# ATmega16U4 device description
Architecture: AVR8; Family: megaAVR
Registers are 8-bit, access not given, no defined reset value unless marked. A register's access mark holds for its fields unless they carry their own. Offsets are from the block's base; [hi:lo] are bit positions.

## BOOT_LOAD — Bootloader
Instances: BOOT_LOAD 0x00
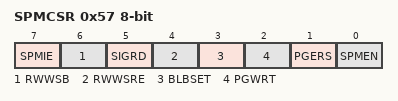
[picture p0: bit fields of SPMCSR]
0x57 SPMCSR — Store Program Memory Control Register
  [7] SPMIE — SPM Interrupt Enable
  [6] RWWSB — Read While Write Section Busy
  [5] SIGRD — Signature Row Read
  [4] RWWSRE — Read While Write section read enable
  [3] BLBSET — Boot Lock Bit Set
  [2] PGWRT — Page Write
  [1] PGERS — Page Erase
  [0] SPMEN — Store Program Memory Enable

## EEPROM
Instances: EEPROM 0x00
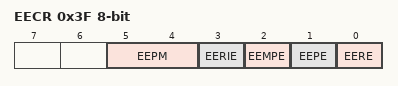
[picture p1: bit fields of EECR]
0x3F EECR — EEPROM Control Register
  [5:4] EEPM — EEPROM Programming Mode Bits
    0=Erase and Write in one operation; 1=Erase Only; 2=Write Only
  [3] EERIE — EEPROM Ready Interrupt Enable
  [2] EEMPE — EEPROM Master Write Enable
  [1] EEPE — EEPROM Write Enable
  [0] EERE — EEPROM Read Enable
0x40 EEDR — EEPROM Data Register
  [7:0] EEDR — EEPROM Data Bits
0x41 EEAR 16-bit — EEPROM Address Register Low Bytes
  [11:0] EEAR — EEPROM Address Bits

## TC0 (TC8 module) — Timer/Counter, 8-bit
Instances: TC0 0x00
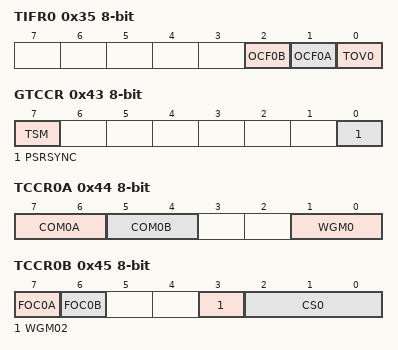
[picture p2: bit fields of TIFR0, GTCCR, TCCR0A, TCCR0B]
0x35 TIFR0 — Timer/Counter0 Interrupt Flag register
  [2] OCF0B — Timer/Counter0 Output Compare Flag 0B
  [1] OCF0A — Timer/Counter0 Output Compare Flag 0A
  [0] TOV0 — Timer/Counter0 Overflow Flag
0x43 GTCCR — General Timer/Counter Control Register
  [7] TSM — Timer/Counter Synchronization Mode
  [0] PSRSYNC — Prescaler Reset Timer/Counter1 and Timer/Counter0
0x44 TCCR0A — Timer/Counter Control Register A
  [7:6] COM0A — Compare Output Mode, Phase Correct PWM Mode
  [5:4] COM0B — Compare Output Mode, Fast PWm
  [1:0] WGM0 — Waveform Generation Mode
0x45 TCCR0B — Timer/Counter Control Register B
  [7] FOC0A — Force Output Compare A
  [6] FOC0B — Force Output Compare B
  [3] WGM02
  [2:0] CS0 — Clock Select
    0=No Clock Source (Stopped); 1=Running, No Prescaling; 2=Running, CLK/8; 3=Running, CLK/64; 4=Running, CLK/256; 5=Running, CLK/1024; 6=Running, ExtClk Tx Falling Edge; 7=Running, ExtClk Tx Rising Edge
0x46 TCNT0 — Timer/Counter0
  [7:0] TCNT0 — Timer/Counter0 bits
0x47 OCR0A — Timer/Counter0 Output Compare Register
  [7:0] OCR0A — Timer/Counter0 Output Compare A bits
0x48 OCR0B — Timer/Counter0 Output Compare Register
  [7:0] OCR0B — Timer/Counter0 Output Compare B bits
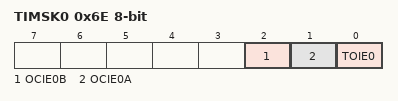
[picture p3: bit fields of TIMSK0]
0x6E TIMSK0 — Timer/Counter0 Interrupt Mask Register
  [2] OCIE0B — Timer/Counter0 Output Compare Match B Interrupt Enable
  [1] OCIE0A — Timer/Counter0 Output Compare Match A Interrupt Enable
  [0] TOIE0 — Timer/Counter0 Overflow Interrupt Enable

## TC4 (TC10 module) — Timer/Counter, 10-bit
Instances: TC4 0x00
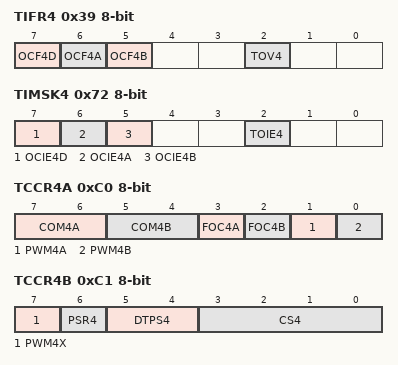
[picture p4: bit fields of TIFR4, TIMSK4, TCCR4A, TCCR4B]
0x39 TIFR4 — Timer/Counter4 Interrupt Flag register
  [7] OCF4D — Output Compare Flag 4D
  [6] OCF4A — Output Compare Flag 4A
  [5] OCF4B — Output Compare Flag 4B
  [2] TOV4 — Timer/Counter4 Overflow Flag
0x72 TIMSK4 — Timer/Counter4 Interrupt Mask Register
  [7] OCIE4D — Timer/Counter4 Output Compare D Match Interrupt Enable
  [6] OCIE4A — Timer/Counter4 Output Compare A Match Interrupt Enable
  [5] OCIE4B — Timer/Counter4 Output Compare B Match Interrupt Enable
  [2] TOIE4 — Timer/Counter4 Overflow Interrupt Enable
0xBE TCNT4 — Timer/Counter4 Low Bytes
  [7:0] TC4 — Timer/Counter4 bits
0xBF TC4H — Timer/Counter4
  [2:0] TC4 (bit 8 of the value upward) — Timer/Counter4 bits
0xC0 TCCR4A — Timer/Counter4 Control Register A
  [7:6] COM4A — Compare Output Mode 1A, bits
  [5:4] COM4B — Compare Output Mode 4B, bits
  [3] FOC4A — Force Output Compare Match 4A
  [2] FOC4B — Force Output Compare Match 4B
  [1] PWM4A
  [0] PWM4B
0xC1 TCCR4B — Timer/Counter4 Control Register B
  [7] PWM4X — PWM Inversion Mode
  [6] PSR4 — Prescaler Reset Timer/Counter 4
  [5:4] DTPS4 — Dead Time Prescaler Bits
  [3:0] CS4 — Clock Select Bits
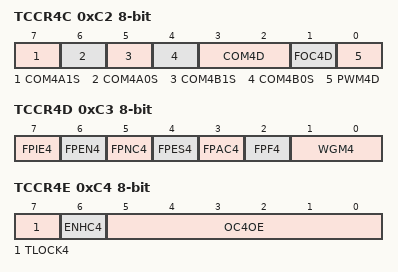
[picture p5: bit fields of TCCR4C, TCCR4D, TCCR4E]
0xC2 TCCR4C — Timer/Counter 4 Control Register C
  [7] COM4A1S — Comparator A Output Mode
  [6] COM4A0S — Comparator A Output Mode
  [5] COM4B1S — Comparator B Output Mode
  [4] COM4B0S — Comparator B Output Mode
  [3:2] COM4D — Comparator D Output Mode
  [1] FOC4D — Force Output Compare Match 4D
  [0] PWM4D — Pulse Width Modulator D Enable
0xC3 TCCR4D — Timer/Counter 4 Control Register D
  [7] FPIE4 — Fault Protection Interrupt Enable
  [6] FPEN4 — Fault Protection Mode Enable
  [5] FPNC4 — Fault Protection Noise Canceler
  [4] FPES4 — Fault Protection Edge Select
  [3] FPAC4 — Fault Protection Analog Comparator Enable
  [2] FPF4 — Fault Protection Interrupt Flag
  [1:0] WGM4 — Waveform Generation Mode bits
0xC4 TCCR4E — Timer/Counter 4 Control Register E
  [7] TLOCK4 — Register Update Lock
  [6] ENHC4 — Enhanced Compare/PWM Mode
  [5:0] OC4OE — Output Compare Override Enable bit
0xCF OCR4A — Timer/Counter4 Output Compare Register A
  [7:0] OCR4A — Timer/Counter4 Output Compare A bits
0xD0 OCR4B — Timer/Counter4 Output Compare Register B
  [7:0] OCR4B — Timer/Counter4 Output Compare B bits
0xD1 OCR4C — Timer/Counter4 Output Compare Register C
  [7:0] OCR4C — Timer/Counter4 Output Compare C bits
0xD2 OCR4D — Timer/Counter4 Output Compare Register D
  [7:0] OCR4D — Timer/Counter4 Output Compare D bits
0xD4 DT4 — Timer/Counter 4 Dead Time Value
  [7:0] DT4L — Timer/Counter 4 Dead Time Value Bits
